# CPU_MPU register map
Vendor: Texas Instruments
Peripheral module from a debugger description file (folder CC26x4).
Registers are 32-bit, access per field, reset 0x0 unless marked. A register's access mark holds for its fields unless they carry their own. Offsets are as the file gives them; lines under a group give offsets from that group; [hi:lo] are bit positions; {n}, {i} and the like mark numbered series; 'fields as' and 'values as' point back to an identical list; <NAME> marks a mode.

## CPU_MPU — Cortex-M's Memory Protection Unit (MPU)
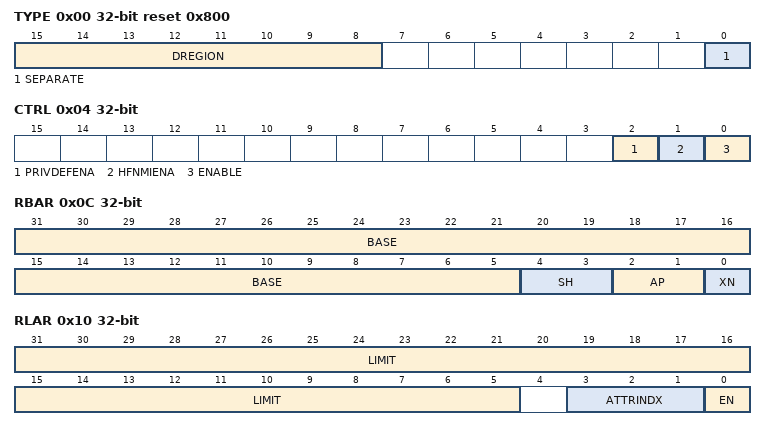
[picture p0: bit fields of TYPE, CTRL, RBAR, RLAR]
0x00 TYPE ro reset 0x800 — The MPU Type Register indicates how many regions the MPU supports
  [15:8] DREGION — Number of regions supported by the MPU
  [0] SEPARATE — Indicates support for separate instructions and data address regions
0x04 CTRL — Enables the MPU and, when the MPU is enabled, controls whether the default memory map is enabled as a background region for privileged accesses, and whether the MPU is enabled for HardFaults, NMIs, and exception handlers when FAULTMASK is set to 1
  [2] PRIVDEFENA rw — Controls whether the default memory map is enabled for privileged software
  [1] HFNMIENA rw — Controls whether handlers executing with priority less than 0 access memory with the MPU enabled or disabled. This applies to HardFaults, NMIs, and exception handlers when FAULTMASK is set to 1
  [0] ENABLE rw — Enables the MPU
0x08 RNR — Selects the region currently accessed by MPU_RBAR and MPU_RLAR
  [7:0] REGION rw — Indicates the memory region accessed by MPU_RBAR and MPU_RLAR
0x0C RBAR rw — Provides indirect read and write access to the base address of the currently selected MPU region
  [31:5] BASE — Contains bits [31:5] of the lower inclusive limit of the selected MPU memory region. This value is zero extended to provide the base address to be checked against
  [4:3] SH — Defines the Shareability domain of this region for Normal memory
  [2:1] AP — Defines the access permissions for this region
  [0] XN — Defines whether code can be executed from this region
0x10 RLAR — Provides indirect read and write access to the limit address of the currently selected MPU region
  [31:5] LIMIT rw — Contains bits [31:5] of the upper inclusive limit of the selected MPU memory region. This value is postfixed with 0x1F to provide the limit address to be checked against
  [3:1] ATTRINDX rw — Associates a set of attributes in the MPU_MAIR0 and MPU_MAIR1 fields
  [0] EN rw — Region enable
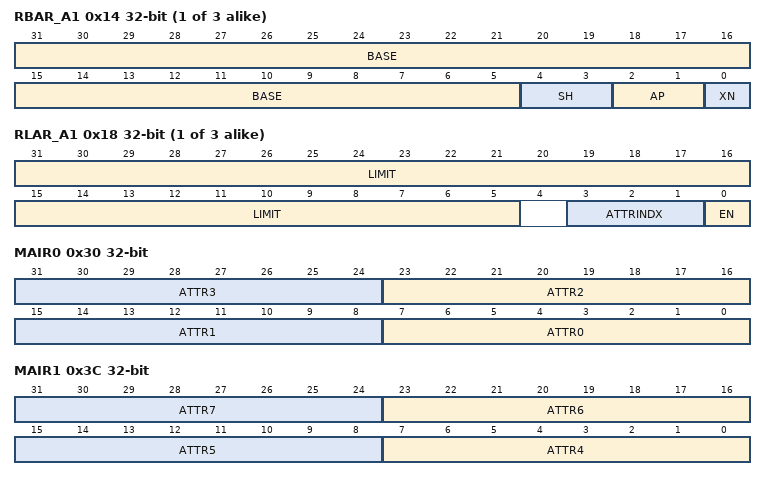
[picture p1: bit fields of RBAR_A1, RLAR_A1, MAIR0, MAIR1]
{0xC+8i} RBAR_A{i} rw (i=1..3) — Provides indirect read and write access to the base address of the MPU region selected by MPU_RNR[7:2]:({i}[1:0])
  fields as RBAR
{0x10+8i} RLAR_A{i} (i=1..3) — Provides indirect read and write access to the limit address of the currently selected MPU region selected by MPU_RNR[7:2]:({i}[1:0])
  fields as RLAR
0x30 MAIR0 rw — Along with MPU_MAIR1, provides the memory attribute encodings corresponding to the AttrIndex values
  [8n+7:8n] ATTR{n} (n=0..3) — Memory attribute encoding for MPU regions with an AttrIndex of {n}
0x3C MAIR1 rw — Along with MPU_MAIR0, provides the memory attribute encodings corresponding to the AttrIndex values
  [8n-25:8n-32] ATTR{n} (n=4..7) — Memory attribute encoding for MPU regions with an AttrIndex of {n}
